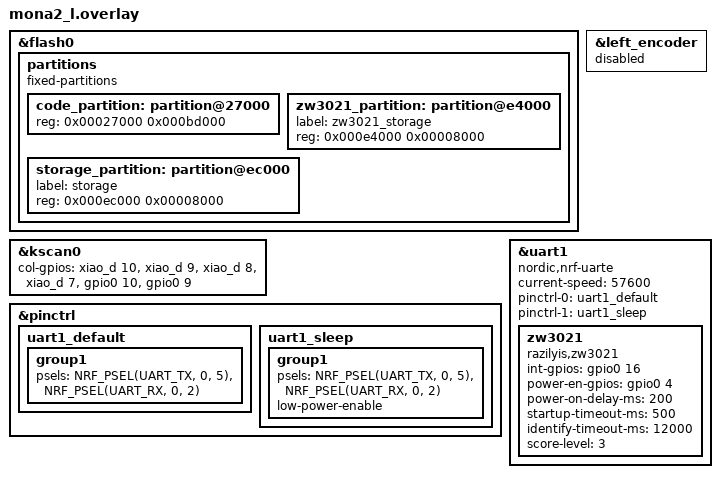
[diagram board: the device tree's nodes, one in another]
#include "mona2.dtsi"

// Carve out a dedicated NVS partition for ZW3021 per-fingerprint output
// strings (Left only -- this is where the sensor and its NVS storage
// live). Shrinks code_partition to make room, following the exact same
// pattern as zmk-config-TouchPass's touchpass.overlay.
&flash0 {
    partitions {
        compatible = "fixed-partitions";
        #address-cells = <1>;
        #size-cells = <1>;

        /* Shrunk from 0x000c5000 to make room for zw3021_partition below. */
        code_partition: partition@27000 {
            reg = <0x00027000 0x000bd000>;
        };

        /* ZW3021 per-fingerprint output strings (NVS), separate from ZMK's
         * own settings/BLE-bonding NVS in storage_partition below. Never
         * committed to git -- written at runtime only, via the serial RPC
         * interface in zmk-driver-zw3021's src/serial_rpc.c. */
        zw3021_partition: partition@e4000 {
            label = "zw3021_storage";
            reg = <0x000e4000 0x00008000>;
        };

        storage_partition: partition@ec000 {
            label = "storage";
            reg = <0x000ec000 0x00008000>;
        };
    };
};

&kscan0 {
        col-gpios
            = <&xiao_d 10 GPIO_ACTIVE_HIGH>
            , <&xiao_d 9 GPIO_ACTIVE_HIGH>
            , <&xiao_d 8 GPIO_ACTIVE_HIGH>
            , <&xiao_d 7 GPIO_ACTIVE_HIGH>
            , <&gpio0 10 GPIO_ACTIVE_HIGH>
            , <&gpio0 9 GPIO_ACTIVE_HIGH>
            ;
};

// ZW3021 fingerprint module takes over the rotary encoder's position
// (D5/D0) plus D4 and a direct wire to P0.16; see zmk-driver-zw3021/README.md.
&left_encoder {
    status = "disabled";
};

&pinctrl {
    uart1_default: uart1_default {
        group1 {
            psels = <NRF_PSEL(UART_TX, 0, 5)>,   /* D5 */
                    <NRF_PSEL(UART_RX, 0, 2)>;    /* D0 */
        };
    };
    uart1_sleep: uart1_sleep {
        group1 {
            psels = <NRF_PSEL(UART_TX, 0, 5)>,
                    <NRF_PSEL(UART_RX, 0, 2)>;
            low-power-enable;
        };
    };
};

&uart1 {
    status = "okay";
    compatible = "nordic,nrf-uarte";
    current-speed = <57600>;
    pinctrl-0 = <&uart1_default>;
    pinctrl-1 = <&uart1_sleep>;
    pinctrl-names = "default", "sleep";

    zw3021: zw3021 {
        compatible = "razilyis,zw3021";
        status = "okay";

        /* P0.16 is not on the XIAO D0-D10 header; wired directly to the
         * nRF52840 module (confirmed accessible/solderable on this board). */
        int-gpios = <&gpio0 16 (GPIO_PULL_DOWN | GPIO_ACTIVE_HIGH)>;
        power-en-gpios = <&gpio0 4 GPIO_ACTIVE_HIGH>; /* D4 */

        power-on-delay-ms = <200>;
        startup-timeout-ms = <500>;
        identify-timeout-ms = <12000>;
        score-level = <3>;
    };
};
